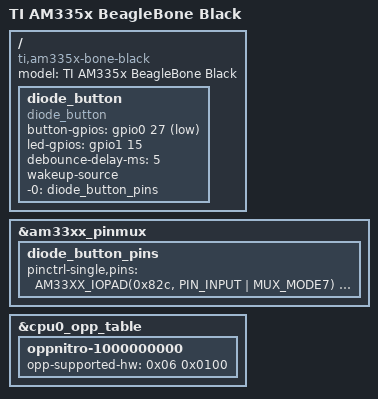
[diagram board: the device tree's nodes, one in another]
/*
 * Copyright (C) 2012 Texas Instruments Incorporated - http://www.ti.com/
 *
 * This program is free software; you can redistribute it and/or modify
 * it under the terms of the GNU General Public License version 2 as
 * published by the Free Software Foundation.
 */
/dts-v1/;

#include "am33xx.dtsi"
#include "am335x-bone-common.dtsi"
#include "am335x-boneblack-common.dtsi"

&am33xx_pinmux {
	diode_button_pins: diode_button_pins {
		pinctrl-single,pins = <
			AM33XX_IOPAD(0x82c, PIN_INPUT | MUX_MODE7) /* gpmc_ad11.gpio0_27 */
			AM33XX_IOPAD(0x83c, PIN_OUTPUT | MUX_MODE7) /* gpmc_ad15.gpio1_15 */
		>;
	};
};

/ {
	model = "TI AM335x BeagleBone Black";
	compatible = "ti,am335x-bone-black", "ti,am335x-bone", "ti,am33xx";

	diode_button {
		compatible = "diode_button";
		button-gpios = <&gpio0 27 GPIO_ACTIVE_LOW >;
		led-gpios = <&gpio1 15 GPIO_ACTIVE_HIGH >;
		debounce-delay-ms = <5>;
		wakeup-source;
		pinctrl-names = "default";
		pinctrl -0 = <&diode_button_pins>;
	};
};

&cpu0_opp_table {
	/*
	 * All PG 2.0 silicon may not support 1GHz but some of the early
	 * BeagleBone Blacks have PG 2.0 silicon which is guaranteed
	 * to support 1GHz OPP so enable it for PG 2.0 on this board.
	 */
	oppnitro-1000000000 {
		opp-supported-hw = <0x06 0x0100>;
	};
};
